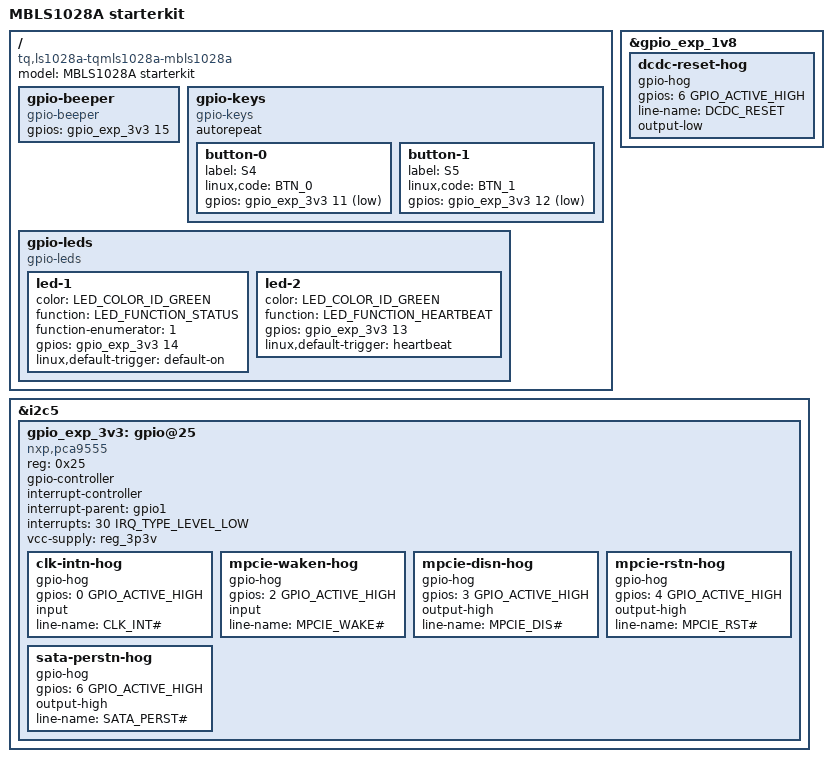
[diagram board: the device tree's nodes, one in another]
// SPDX-License-Identifier: (GPL-2.0-or-later OR MIT)
/*
 * Copyright 2019-2025 TQ-Systems GmbH <linux@ew.tq-group.com>,
 * D-82229 Seefeld, Germany.
 * Author: Michael Krummsdorf
 * Author: Matthias Schiffer
 * Author: Alexander Stein
 */

/dts-v1/;

#include <dt-bindings/input/input.h>
#include <dt-bindings/leds/common.h>
#include "fsl-ls1028a-tqmls1028a-mbls1028a.dtsi"

/ {
	model = "MBLS1028A starterkit";
	compatible = "tq,ls1028a-tqmls1028a-mbls1028a", "tq,ls1028a-tqmls1028a", "fsl,ls1028a";

	gpio-beeper {
		compatible = "gpio-beeper";
		gpios = <&gpio_exp_3v3 15 GPIO_ACTIVE_HIGH>;
	};

	gpio-keys {
		compatible = "gpio-keys";
		autorepeat;

		button-0 {
			label = "S4";
			linux,code = <BTN_0>;
			gpios = <&gpio_exp_3v3 11 GPIO_ACTIVE_LOW>;
		};

		button-1 {
			label = "S5";
			linux,code = <BTN_1>;
			gpios = <&gpio_exp_3v3 12 GPIO_ACTIVE_LOW>;
		};
	};

	gpio-leds {
		compatible = "gpio-leds";

		led-1 {
			color = <LED_COLOR_ID_GREEN>;
			function = LED_FUNCTION_STATUS;
			function-enumerator = <1>;
			gpios = <&gpio_exp_3v3 14 GPIO_ACTIVE_HIGH>;
			linux,default-trigger = "default-on";
		};

		led-2 {
			color = <LED_COLOR_ID_GREEN>;
			function = LED_FUNCTION_HEARTBEAT;
			gpios = <&gpio_exp_3v3 13 GPIO_ACTIVE_HIGH>;
			linux,default-trigger = "heartbeat";
		};
	};
};

&gpio_exp_1v8 {
	dcdc-reset-hog {
		gpio-hog;
		gpios = <6 GPIO_ACTIVE_HIGH>;
		line-name = "DCDC_RESET";
		output-low;
	};
};

&i2c5 {
	gpio_exp_3v3: gpio@25 {
		compatible = "nxp,pca9555";
		reg = <0x25>;
		#gpio-cells = <2>;
		gpio-controller;
		#interrupt-cells = <2>;
		interrupt-controller;
		interrupt-parent = <&gpio1>;
		interrupts = <30 IRQ_TYPE_LEVEL_LOW>;
		vcc-supply = <&reg_3p3v>;

		clk-intn-hog {
			gpio-hog;
			gpios = <0 GPIO_ACTIVE_HIGH>;
			input;
			line-name = "CLK_INT#";
		};

		mpcie-waken-hog {
			gpio-hog;
			gpios = <2 GPIO_ACTIVE_HIGH>;
			input;
			line-name = "MPCIE_WAKE#";
		};

		mpcie-disn-hog {
			gpio-hog;
			gpios = <3 GPIO_ACTIVE_HIGH>;
			output-high;
			line-name = "MPCIE_DIS#";
		};

		mpcie-rstn-hog {
			gpio-hog;
			gpios = <4 GPIO_ACTIVE_HIGH>;
			output-high;
			line-name = "MPCIE_RST#";
		};

		sata-perstn-hog {
			gpio-hog;
			gpios = <6 GPIO_ACTIVE_HIGH>;
			output-high;
			line-name = "SATA_PERST#";
		};
	};
};
